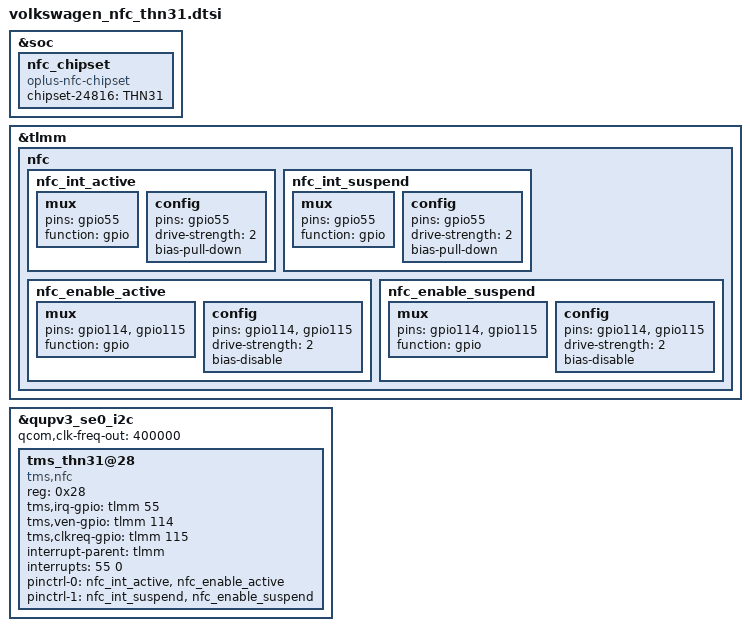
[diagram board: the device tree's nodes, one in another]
#include <dt-bindings/clock/qcom,rpmh.h>

&soc {
    //add for nfc_chipset
    nfc_chipset {
        compatible = "oplus-nfc-chipset";
        chipset-24816 = "THN31";
    };
};
&tlmm {
	nfc {
		nfc_int_active: nfc_int_active {
			/* active state */
			mux {
				/* NFC Read Interrupt */
				pins = "gpio55";
				function = "gpio";
			};

			config {
				pins = "gpio55";
				drive-strength = <2>; /* 2 MA */
				bias-pull-down;
			};
		};

		nfc_int_suspend: nfc_int_suspend {
			/* sleep state */
			mux {
				/* NFC Read Interrupt */
				pins = "gpio55";
				function = "gpio";
			};

			config {
				pins = "gpio55";
				drive-strength = <2>; /* 2 MA */
				bias-pull-down;
			};
		};

		nfc_enable_active: nfc_enable_active {
			mux {
				/* Enable, and Clock request gpios */
				pins = "gpio114", "gpio115";
				function = "gpio";
			};

			config {
				pins = "gpio114", "gpio115";
				drive-strength = <2>; /* 2 MA */
				bias-disable;
			};
		};

		nfc_enable_suspend: nfc_enable_suspend {
			mux {
				pins = "gpio114", "gpio115";
				function = "gpio";
			};

			config {
				pins = "gpio114", "gpio115";
				drive-strength = <2>; /* 2 MA */
				bias-disable;
			};
		};
	}; //nfc
}; //tlmm
&qupv3_se0_i2c {
	status = "ok";
	qcom,clk-freq-out = <400000>;
	#address-cells = <1>;
	#size-cells = <0>;
	tms_thn31@28 {
		compatible = "tms,nfc";
		reg = <0x28>;
		tms,irq-gpio = <&tlmm 55 0x00>;
		tms,ven-gpio = <&tlmm 114 0x00>;
		tms,clkreq-gpio = <&tlmm 115 0x00>;
		interrupt-parent = <&tlmm>;
		interrupts = <55 0>;
		interrupt-names = "nfc_irq";
		pinctrl-names = "nfc_active", "nfc_suspend";
		pinctrl-0 = <&nfc_int_active &nfc_enable_active>;
		pinctrl-1 = <&nfc_int_suspend &nfc_enable_suspend>;
	};
};
